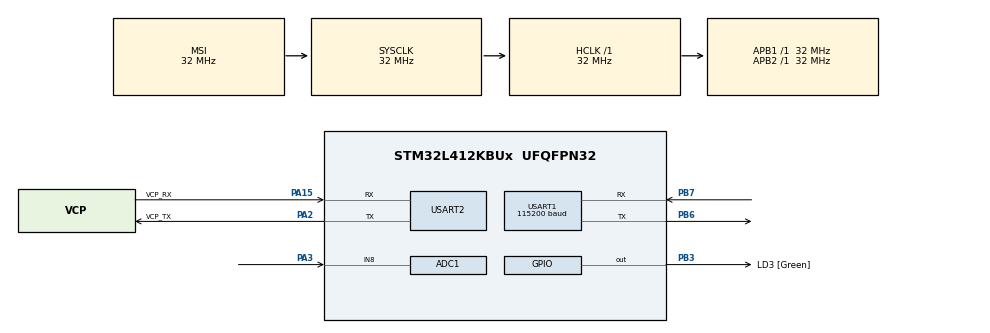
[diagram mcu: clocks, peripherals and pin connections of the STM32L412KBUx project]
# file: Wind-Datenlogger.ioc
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ADC1.Channel-0\#ChannelRegularConversion=ADC_CHANNEL_8
ADC1.ContinuousConvMode=ENABLE
ADC1.NbrOfConversionFlag=1
ADC1.OffsetNumber-0\#ChannelRegularConversion=ADC_OFFSET_NONE
ADC1.Rank-0\#ChannelRegularConversion=1
ADC1.SamplingTime-0\#ChannelRegularConversion=ADC_SAMPLETIME_2CYCLES_5
ADC1.master=1
Mcu.Family=STM32L4
Mcu.Name=STM32L412KBUx
Mcu.Package=UFQFPN32
NVIC.PriorityGroup=NVIC_PRIORITYGROUP_4
PA0-CK_IN.Mode=HSE-External-Clock-Source-for-LittleOrca
PA0-CK_IN.Signal=RCC_CK_IN
PA13\ (JTMS/SWDIO).GPIO_Label=SWDIO
PA13\ (JTMS/SWDIO).Mode=Serial_Wire
PA13\ (JTMS/SWDIO).Signal=SYS_JTMS-SWDIO
PA14\ (JTCK/SWCLK).GPIO_Label=SWCLK
PA14\ (JTCK/SWCLK).Mode=Serial_Wire
PA14\ (JTCK/SWCLK).Signal=SYS_JTCK-SWCLK
PA15\ (JTDI).GPIO_Label=VCP_RX
PA15\ (JTDI).Mode=Asynchronous
PA15\ (JTDI).Signal=USART2_RX
PA2.GPIO_Label=VCP_TX
PA2.Mode=Asynchronous
PA2.Signal=USART2_TX
PA3.Signal=ADCx_IN8
PB3\ (JTDO/TRACESWO).GPIO_Label=LD3 [Green]
PB3\ (JTDO/TRACESWO).Signal=GPIO_Output
PB6.Mode=Asynchronous
PB6.Signal=USART1_TX
PB7.Mode=Asynchronous
PB7.Signal=USART1_RX
PC14-OSC32_IN\ (PC14).Mode=LSE-External-Oscillator
PC14-OSC32_IN\ (PC14).Signal=RCC_OSC32_IN
PC15-OSC32_OUT\ (PC15).Mode=LSE-External-Oscillator
PC15-OSC32_OUT\ (PC15).Signal=RCC_OSC32_OUT
ProjectManager.HeapSize=0x200
ProjectManager.StackSize=0x400
ProjectManager.TargetToolchain=SW4STM32
RCC.ADCFreq_Value=32000000
RCC.AHBFreq_Value=32000000
RCC.APB1Freq_Value=32000000
RCC.APB1TimFreq_Value=32000000
RCC.APB2Freq_Value=32000000
RCC.APB2TimFreq_Value=32000000
RCC.CortexFreq_Value=32000000
RCC.FLatency=FLASH_LATENCY_1
RCC.HCLKFreq_Value=32000000
RCC.HSE_VALUE=8000000
RCC.HSI48_VALUE=48000000
RCC.HSICalibrationValue=16
RCC.HSI_VALUE=16000000
RCC.LSE_Drive_Capability=RCC_LSEDRIVE_LOW
RCC.MSIClockRange=RCC_MSIRANGE_10
RCC.MSI_VALUE=32000000
RCC.SYSCLKFreq_VALUE=32000000
RCC.USBFreq_Value=32000000
RCC.VCOOutputFreq_Value=256000000
SH.ADCx_IN8.0=ADC1_IN8,IN8-Single-Ended
USART1.BaudRate=115200
USART1.VirtualMode-Asynchronous=VM_ASYNC
USART2.VirtualMode-Asynchronous=VM_ASYNC
board=NUCLEO-L412KB

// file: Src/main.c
/* USER CODE BEGIN Header */
/**
  ******************************************************************************
  * @file           : main.c
  * @brief          : Main program body
  ******************************************************************************
  * @attention
  *
  * <h2><center>&copy; Copyright (c) 2019 STMicroelectronics.
  * All rights reserved.</center></h2>
  *
  * This software component is licensed by ST under BSD 3-Clause license,
  * the "License"; You may not use this file except in compliance with the
  * License. You may obtain a copy of the License at:
  *                        opensource.org/licenses/BSD-3-Clause
  *
  ******************************************************************************
  */
/* USER CODE END Header */

#include "main.h"
#include "adc.h"
#include "usart.h"
#include "gpio.h"

void SystemClock_Config(void);

/* USER CODE BEGIN 0 */
uint32_t g_ADCValue;
int g_MeasurementNumber;
/* USER CODE END 0 */

int main(void)
{

  /* MCU Configuration--------------------------------------------------------*/

  /* Reset of all peripherals, Initializes the Flash interface and the Systick. */
  HAL_Init();

  /* Configure the system clock */
  SystemClock_Config();

  /* Initialize all configured peripherals */
  MX_GPIO_Init();
  MX_USART1_UART_Init();
  MX_USART2_UART_Init();
  MX_ADC1_Init();

  /* Infinite loop */
  /* USER CODE BEGIN WHILE */

    while (1)
    {
    	ADC_HandleTypeDef g_AdcHandle;

    	__GPIOD_CLK_ENABLE();
    	GPIO_InitTypeDef GPIO_InitStructure;

    	GPIO_InitStructure.Pin = GPIO_PIN_10;

    	HAL_ADC_Start(&g_AdcHandle);
    	for(g_MeasurementNumber = 0; g_MeasurementNumber < 1000; g_MeasurementNumber++)
    	{
    		if(HAL_ADC_PollForConversation(&g_AdcHandle, 100000) == HAL_OK)
    		{
    			g_ADCValue = HAL_ADC_GetValue(&g_AdcHandle);
    			g_MeasurementNumber++;

    			char transmitBuffer[12] = g_ADCValue;
    			HAL_UART_Transmit(&huart1, transmitBuffer, 12, 100);
    		}
    	}

//    	char transmitBuffer[7] = "Chatte\n";
//  	  HAL_GPIO_TogglePin(GPIOB, GPIO_PIN_3);
//  		  HAL_Delay(100);
//  	HAL_UART_Transmit(&huart1, transmitBuffer , 7, 100);
    /* USER CODE END WHILE */

  }
}

void SystemClock_Config(void)
{
  RCC_OscInitTypeDef RCC_OscInitStruct = {0};
  RCC_ClkInitTypeDef RCC_ClkInitStruct = {0};
  RCC_PeriphCLKInitTypeDef PeriphClkInit = {0};

  /** Configure LSE Drive Capability
  */
  HAL_PWR_EnableBkUpAccess();
  __HAL_RCC_LSEDRIVE_CONFIG(RCC_LSEDRIVE_LOW);
  /** Configure the main internal regulator output voltage
  */
  if (HAL_PWREx_ControlVoltageScaling(PWR_REGULATOR_VOLTAGE_SCALE1) != HAL_OK)
  {
    Error_Handler();
  }
  /** Initializes the CPU, AHB and APB busses clocks
  */
  RCC_OscInitStruct.OscillatorType = RCC_OSCILLATORTYPE_LSE|RCC_OSCILLATORTYPE_MSI;
  RCC_OscInitStruct.LSEState = RCC_LSE_ON;
  RCC_OscInitStruct.MSIState = RCC_MSI_ON;
  RCC_OscInitStruct.MSICalibrationValue = 0;
  RCC_OscInitStruct.MSIClockRange = RCC_MSIRANGE_10;
  RCC_OscInitStruct.PLL.PLLState = RCC_PLL_NONE;
  if (HAL_RCC_OscConfig(&RCC_OscInitStruct) != HAL_OK)
  {
    Error_Handler();
  }
  /** Initializes the CPU, AHB and APB busses clocks
  */
  RCC_ClkInitStruct.ClockType = RCC_CLOCKTYPE_HCLK|RCC_CLOCKTYPE_SYSCLK
                              |RCC_CLOCKTYPE_PCLK1|RCC_CLOCKTYPE_PCLK2;
  RCC_ClkInitStruct.SYSCLKSource = RCC_SYSCLKSOURCE_MSI;
  RCC_ClkInitStruct.AHBCLKDivider = RCC_SYSCLK_DIV1;
  RCC_ClkInitStruct.APB1CLKDivider = RCC_HCLK_DIV1;
  RCC_ClkInitStruct.APB2CLKDivider = RCC_HCLK_DIV1;

  if (HAL_RCC_ClockConfig(&RCC_ClkInitStruct, FLASH_LATENCY_1) != HAL_OK)
  {
    Error_Handler();
  }
  PeriphClkInit.PeriphClockSelection = RCC_PERIPHCLK_USART1|RCC_PERIPHCLK_USART2
                              |RCC_PERIPHCLK_ADC;
  PeriphClkInit.Usart1ClockSelection = RCC_USART1CLKSOURCE_PCLK2;
  PeriphClkInit.Usart2ClockSelection = RCC_USART2CLKSOURCE_PCLK1;
  if (HAL_RCCEx_PeriphCLKConfig(&PeriphClkInit) != HAL_OK)
  {
    Error_Handler();
  }
  /** Enable MSI Auto calibration
  */
  HAL_RCCEx_EnableMSIPLLMode();
}

void Error_Handler(void)
{
}

/************************ (C) COPYRIGHT STMicroelectronics *****END OF FILE****/
